# AVR32SD28 register map
Vendor: Atmel; File version: 1.0
CPU: other r0p0, little endian, no MPU, no FPU, 4 interrupt priority bits
Registers are 8-bit, read-write, reset 0x0 unless marked. A register's access mark holds for its fields unless they carry their own. Offsets are from the block's base; [hi:lo] are bit positions; 'fields as' and 'values as' point back to an identical list.

## CLKCTRL — Clock controller
Base 0x00800080
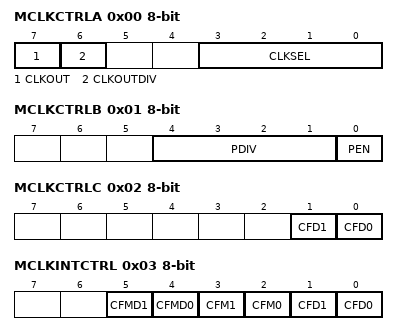
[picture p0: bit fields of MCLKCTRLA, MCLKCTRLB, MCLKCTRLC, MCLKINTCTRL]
0x00 MCLKCTRLA — MCLK Control A
  [7] CLKOUT — System Clock Out
  [6] CLKOUTDIV — Clock Out Divide
    0=DIV1 (Divide by one); 1=DIV32 (Divide by 32)
  [3:0] CLKSEL — Clock Select
    0=OSCHF (Internal high-frequency oscillator); 1=OSC32K (Internal 32.768 kHz oscillator); 2=XOSC32K (32.768 kHz crystal oscillator); 3=EXTCLK (External clock)
0x01 MCLKCTRLB — MCLK Control B
  [4:1] PDIV — Prescaler division
    0=DIV2 (Divide by 2); 1=DIV4 (Divide by 4); 2=DIV8 (Divide by 8); 3=DIV16 (Divide by 16); 4=DIV32 (Divide by 32); 5=DIV64 (Divide by 64); 8=DIV6 (Divide by 6); 9=DIV10 (Divide by 10); 10=DIV12 (Divide by 12); 11=DIV24 (Divide by 24); 12=DIV48 (Divide by 48)
  [0] PEN — Prescaler enable
0x02 MCLKCTRLC — MCLK Control C
  [1] CFD1 — Clock Failure Inject 1
  [0] CFD0 — Clock Failure Inject 0
0x03 MCLKINTCTRL — MCLK Interrupt Control
  [5] CFMD1 — Clock Measurement Done 1
  [4] CFMD0 — Clock Measurement Done 0
  [3] CFM1 — Clock Measurement Failure Detected 1
  [2] CFM0 — Clock Measurement Failure Detected 0
  [1] CFD1 — Clock Failure Detected 1
  [0] CFD0 — Clock Failure Detected 0
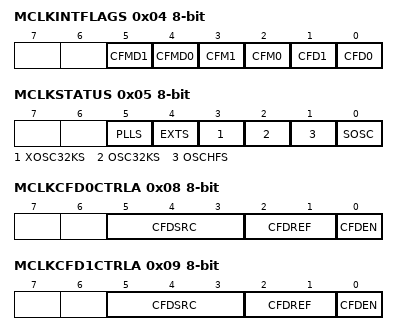
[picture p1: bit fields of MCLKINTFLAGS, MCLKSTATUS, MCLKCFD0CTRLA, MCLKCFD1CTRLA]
0x04 MCLKINTFLAGS — MCLK Interrupt Flags
  fields as MCLKINTCTRL
0x05 MCLKSTATUS ro
  [5] PLLS — PLL Oscillator Status
  [4] EXTS — External Clock Status
  [3] XOSC32KS — 32.768 kHz Crystal Oscillator Status
  [2] OSC32KS — 32KHz Oscillator Status
  [1] OSCHFS — High Frequency Oscillator Status
  [0] SOSC — System Oscillator Changing
0x06 MCLKTIMEBASE
  [4:0] TIMEBASE
0x08 MCLKCFD0CTRLA — MCLK Clock Failure Detect 0 Control A
  [5:3] CFDSRC — Clock Failure Detect Source
    0=MCLK (Main clock as source); 1=OSCHF (OSCHF as source); 2=OSC32K (OSC32K as source); 3=XOSCHF (XOSCHF as source); 4=XOSC32K (XOSC32K as source); 7=EVSYS (Event Channel input)
  [2:1] CFDREF — Clock Failure Detect Reference
    0=OSC32K (OSC32K as reference); 1=ONEDIV32 ((1MHz from OSCHF) / 32 as reference); 2=XOSC32K (XOSC32K as reference)
  [0] CFDEN — Clock Failure Detect Enable
0x09 MCLKCFD1CTRLA — MCLK Clock Failure Detect 1 Control A
  fields as MCLKCFD0CTRLA
0x10 MCLKCFM0VALUE 16-bit ro (reset mask 0xFF) — MCLK Clock Failure Measurement 0 Value
0x12 MCLKCFM0WINLT 16-bit (reset mask 0xFF) — MCLK Clock Failure Measurement 0 Window Low Threshold
0x14 MCLKCFM0WINHT 16-bit (reset mask 0xFF) — MCLK Clock Failure Measurement 0 Window High Threshold
0x16 MCLKCFM0REFNUM 16-bit (reset mask 0xFF) — MCLK Clock Failure Measurement 0 Reference Clock Cycles
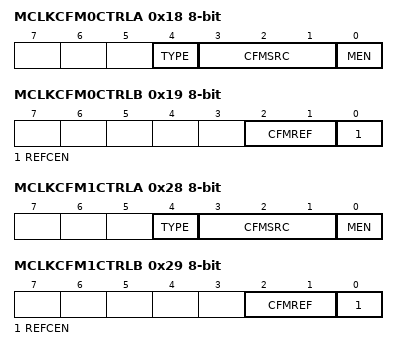
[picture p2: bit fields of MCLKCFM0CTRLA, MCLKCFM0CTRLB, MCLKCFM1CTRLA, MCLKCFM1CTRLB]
0x18 MCLKCFM0CTRLA — MCLK Clock Failure Measurement 0 Control A
  [4] TYPE — Measurement Type
    0=ONESHOT (One-shot measurement); 1=CONTINUOUS (Continuous measurement)
  [3:1] CFMSRC — CFM Clock Reference
    0=CLK_MAIN (Measure Main clock); 1=OSCHF (Measure high frequency oscillator); 2=OSC32K (Measure OSC32K); 3=XOSCHF (Measure high frequency external oscillator); 4=XOSC32K (Measure 32K external oscillator); 5=EVSYS (Measure event system channel)
  [0] MEN — Measurement Enable
0x19 MCLKCFM0CTRLB — MCLK Clock Failure Measurement 0 Control B
  [2:1] CFMREF — CFM Reference Source
    0=OSCHF (High-frequency oscillator as reference); 1=XOSCHF (External high-frequency oscillator as reference); 2=XOSC32K (External 32K oscillator as reference); 3=OSC32K (32K oscillator as reference)
  [0] REFCEN — Reference Clock Enable
0x20 MCLKCFM1VALUE 16-bit ro (reset mask 0xFF) — MCLK Clock Failure Measurement 1 Value
0x22 MCLKCFM1WINLT 16-bit (reset mask 0xFF) — MCLK Clock Failure Measurement 1 Window Low Threshold
0x24 MCLKCFM1WINHT 16-bit (reset mask 0xFF) — MCLK Clock Failure Measurement 1 Window High Threshold
0x26 MCLKCFM1REFNUM 16-bit (reset mask 0xFF) — MCLK Clock Failure Measurement 1 Reference Clock Cycles
0x28 MCLKCFM1CTRLA — MCLK Clock Failure Measurement 1 Control A
  fields as MCLKCFM0CTRLA
0x29 MCLKCFM1CTRLB — MCLK Clock Failure Measurement 1 Control B
  fields as MCLKCFM0CTRLB
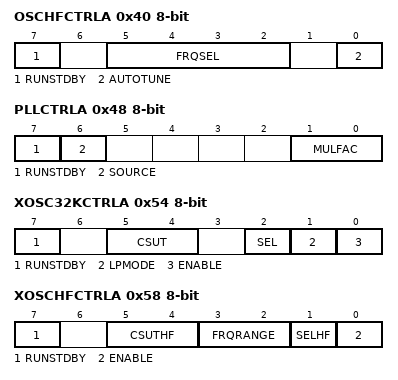
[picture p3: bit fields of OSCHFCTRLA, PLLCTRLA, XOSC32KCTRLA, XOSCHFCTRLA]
0x40 OSCHFCTRLA — OSCHF Control A
  [7] RUNSTDBY — Run in Standby
  [5:2] FRQSEL — Frequency select
    0=1M (1 MHz system clock); 1=2M (2 MHz system clock); 2=3M (3 MHz system clock); 3=4M (4 MHz system clock (default)); 5=8M (8 MHz system clock); 6=12M (12 MHz system clock); 7=16M (16 MHz system clock); 8=20M (20 MHz system clock)
  [0] AUTOTUNE
    0=OFF (Automatic oscillator frequency tune disabled); 1=ON (Automatic oscillator frequency tune enabled)
0x41 OSCHFTUNE
  [7:0] TUNE — Oscillator Tune
0x48 PLLCTRLA — PLL Control A
  [7] RUNSTDBY — Run in Standby
  [6] SOURCE
    0=OSCHF (High frequency internal oscillator as PLL source); 1=EXTCLK (High frequency external clock or external high frequency oscillator as PLL source)
  [1:0] MULFAC — Multiplication Factor
    0=DISABLE (PLL is disabled); 1=X2 (2 x multiplication factor); 2=X3 (3 x multiplication factor)
0x50 OSC32KCTRLA — OSC32K Control A
  [7] RUNSTDBY — Run in Standby
0x54 XOSC32KCTRLA — XOSC32K Control A
  [7] RUNSTDBY — Run in Standby
  [5:4] CSUT — Crystal Oscillator Startup Time
    0=1K (1k cycles); 1=16K (16k cycles); 2=32K (32k cycles); 3=64K (64k cycles)
  [2] SEL — Crystal Selection
    0=XTAL (External crystal); 1=EXTCLK (External clock on XTAL32K1 pin)
  [1] LPMODE — Low-power Mode
    0=OFF (Low-power mode disabled); 1=ON (Low-power mode enabled)
  [0] ENABLE
0x58 XOSCHFCTRLA — XTALHF Control A
  [7] RUNSTDBY — Run in Standby
  [5:4] CSUTHF — Start-up Time
    0=256 XOSCHF cycles; 1=1K (1K XOSCHF cycles); 2=4K (4K XOSCHF cycles)
  [3:2] FRQRANGE — Frequency Range
    0=8M (Max 8 MHz XTAL Frequency); 1=16M (Max 16 MHz XTAL Frequency); 2=24M (Max 24 MHz XTAL Frequency); 3=32M (Max 32 MHz XTAL Frequency)
  [1] SELHF — External Source Select
    0=XTAL (External Crystal); 1=EXTCLK (External clock on XTALHF1 pin)
  [0] ENABLE
